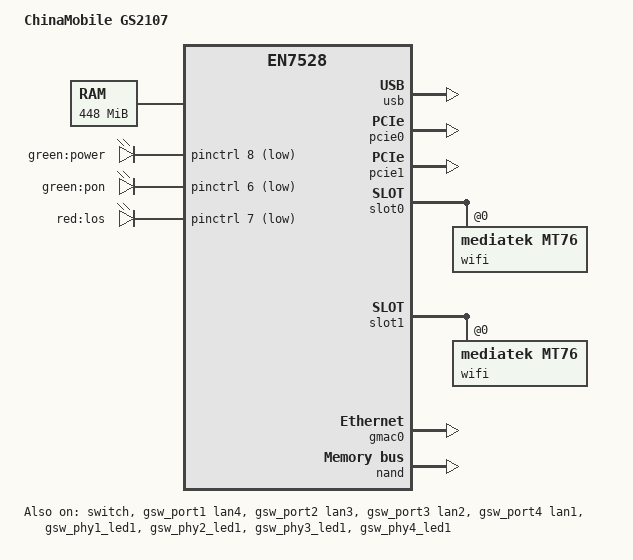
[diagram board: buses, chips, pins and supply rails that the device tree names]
// SPDX-License-Identifier: GPL-2.0-only OR BSD-2-Clause
/*
 * ChinaMobile GS2107（中移杭研智能家庭网关）— EcoNet EN7528
 *
 * 全部标注 [实测] 的事实来自 2026-11-06 亲验（devices/gs2107/ 下文档）：
 *  - SoC: EcoNet EN7528，MIPS1004Kc V2.15 双核 4 VPE，小端 [实测]
 *  - RAM: 运行时 MemTotal=410124kB；DDR 物理容量与厂商预留区待 VMLINUX-RE 确认
 *  - Flash: 256MB SPI NAND，11 分区（本 DTS 与 /proc/mtd 实测逐字节对齐）[实测]
 *  - WiFi: MT7603E(2.4G) + MT7663E(5G)，均 PCIe；
 *          domain0(pcie0)=MT7663E、domain1(pcie1)=MT7603E [实测 /sys/bus/pci]
 *  - 交换: EN7528 内置 GSW + 4 内部 GPHY [实测 eth.ko 的 macMT7530 API / EN7570]
 *  - MAC: bootloader 分区 +0x3fe48（与 JioFiber 同偏移）[实测]
 *  - Bootloader: ECNT tcboot，HDR2+LZMA 镜像，"free bootbase"（解压目标 0x80002000）[实测]
 *  - EEPROM: 2.4G 512B / 5G 1536B 在 rootfs 文件里，不在 NAND 固定偏移 [实测]
 *
 * 模板来源：OpenWrt master target/linux/econet（en7528.dtsi + jiofiber/dasan 板级文件），
 * JioFiber 与本机同 bootloader 变体（free bootbase / TRX_LOADADDR 0x80002000）。
 */

/dts-v1/;

#include "en7528.dtsi"

#include <dt-bindings/gpio/gpio.h>
#include <dt-bindings/input/input.h>
#include <dt-bindings/leds/common.h>

/ {
	model = "ChinaMobile GS2107";
	compatible = "chinamobile,gs2107", "econet,en7528";

	aliases {
		serial0 = &uart;
		led-boot = &led_power;
		led-failsafe = &led_power;
		led-running = &led_power;
		led-upgrade = &led_power;
	};

	memory@0 {
		device_type = "memory";
		/*
		 * 448MB 物理（VMLINUX-RE 实证：cal_qdma_init_buffer(448)；
		 * 运行时 MemTotal 410124kB ≈ 448MB - 约 47MB 内核 BSS/预留，
		 * 其中 BSS 0x80AE0000-0x81BB9B4C 达 17.9MB）。
		 * 构建配置 profile.cfg 的 TCSUPPORT_SDRAM_128M=y 已证伪（过期模板）。
		 * 与 JioFiber JCOW414 完全同值。
		 */
		reg = <0x00000000 0x1c000000>;
	};

	reserved-memory {
		#address-cells = <1>;
		#size-cells = <1>;
		ranges;

		/* 崩溃现场（pstore/ramoops）：panic、oops 与锁死检测触发的 panic 把内核日志写进这里，热复位（看门狗、sysrq、panic 重启）后由 /sys/fs/pstore 读出。放在 384 MB 处：U-Boot 只用 256 MB 以内（board_get_usable_ram_top 把重定位上限钳在 0x90000000），FIT 加载在 0x82000000；ecc-size 让被启动链覆盖的记录显出来而不是读成乱码。 */
		ramoops@18000000 {
			compatible = "ramoops";
			reg = <0x18000000 0x100000>;
			record-size = <0x20000>;
			console-size = <0x40000>;
			ecc-size = <16>;
		};

		/* U-Boot 启动计数（CONFIG_BOOTCOUNT_GENERIC，CONFIG_SYS_BOOTCOUNT_ADDR = 0xB8100000，即本处经 KSEG1 不缓存的地址）：两个小端 32 位字，偏移 0 是计数、偏移 4 是魔数 0xB001C041；U-Boot 每次启动读出加 1 再存，超过 bootlimit 走 altbootcmd，魔数不符（冷启动）按 0 算，热复位 DRAM 内容保持。紧跟 ramoops 之后，留一页。no-map：内核不把它当普通内存分配，由下面的 bootcount 节点（uboot-bootcount 驱动）按不缓存映射读写。 */
		bootcount_mem: bootcount@18100000 {
			reg = <0x18100000 0x1000>;
			no-map;
		};
	};

	/* 系统起来后由 gs2107-bootok 经这里把 U-Boot 的启动计数清零：uboot-bootcount 驱动给本设备一个 sysfs 属性 count（经 /sys/bus/platform/drivers/uboot-bootcount/ 下的设备链接访问），读出计数（魔数不符时为 0），写入 N 存计数 N 与魔数并读回核对。 */
	bootcount {
		compatible = "u-boot,bootcount-mem";
		memory-region = <&bootcount_mem>;
	};

	/* 命令行只来自 U-Boot：bootm 用 env 的 bootargs 改写 /chosen/bootargs，控制台由 stdout-path 给出。命令行不带 root=：根是 UBI 卷 rootfs，OpenWrt 491 在 attach 时为它建 ubiblock，493 在 ROOT_DEV 未设时把它设为根（devices/openwrt/gs2107 docs/33 §2.2）。 */
	chosen {
		stdout-path = "/serial@1fbf0000:115200";
	};

	/* UBI 设备 ubi_rootfs：&nand 里两段不相邻的分区 ubi_seg0、ubi_seg1 按地址顺序拼成一个 MTD，squashfs 根是卷 rootfs，overlay 是 UBIFS 卷 rootfs_data。attach 只靠 linux,ubi（ubi_notify_add，MTD 何时注册都能 attach）；自救 DTB 由本 DTB 去掉这一条派生，自救系统不自动 attach。分区名避开三个会被 OpenWrt 补丁按名字处理的名字：rootfs（hack 420 在 MTD 注册时把它设成根，抢在 UBI attach 之前）、ubi 与 data（pending 490 在 late_initcall 里自动 attach，自救 DTB 就没法只靠去掉 linux,ubi 保持不 attach）。 */
	ubi-concat {
		compatible = "mtd-concat";
		devices = <&ubi_seg0 &ubi_seg1>;

		partitions {
			compatible = "fixed-partitions";
			#address-cells = <1>;
			#size-cells = <1>;

			ubi_rootfs: partition@0 {	/* mtd8 209M（0x2000000 + 0xb100000），1672 PEB */
				label = "ubi_rootfs";
				reg = <0x0 0x0d100000>;
				compatible = "linux,ubi";
			};
		};
	};

	/*
	 * 面板灯（2026-11-11 固件分析结论）：
	 *  - 电源：GPIO8，低电平点亮。tcboot 启动时已把它拉低（实测 GPIO
	 *    寄存器：OE0 bit8=1、DATA0 bit8=0），所以 OpenWrt 不配也会常亮；
	 *    这里登记成 LED 设备，统一走 led-boot/led-running。
	 *  - PON/LOS：原厂 /userfs/led.conf 的 LED 64/65 -> GPIO6、66/67 ->
	 *    GPIO7（xpon.ko 的 change_alarm_led_status 实测传 0x40..0x43）。
	 *    注意：本机 GPIO6/7 的 mux 位本来就是 0，寄存器级实测可正常拉低/
	 *    拉高，但面板没有反应；这两颗灯很可能挂在 EN7571 PON PHY 的 LED
	 *    控制器上，只有 PON 驱动初始化后才可用。这里保留节点，等 PON 侧
	 *    有能力时直接接管，不让 GPIO 悬空。
	 *  - 网络：原厂 led.conf 的 INTERNET 行全为 0，xpon/tcledctrl 没有给出
	 *    任何 GPIO；没有可写的硬件映射，暂不建节点。
	 *  - 无线：驱动注册 /sys/class/leds/mt76-phy0|phy1，默认触发器 phy0tpt/phy1tpt。2.4G（MT7603E）由 mt76 写芯片 LED 控制器的 pin 0；5G（MT7663E）接在芯片的 LED1，由固件经 MCU 命令 EXT_CMD_ID_LED 驱动（mt76 补丁，见 slot0 的 led 节点）。
	 */
	leds {
		compatible = "gpio-leds";

		led_power: power {
			label = "green:power";
			gpios = <&pinctrl 8 GPIO_ACTIVE_LOW>;
			default-state = "on";
		};

		led_pon: pon {
			label = "green:pon";
			gpios = <&pinctrl 6 GPIO_ACTIVE_LOW>;
			default-state = "off";
		};

		led_los: los {
			label = "red:los";
			gpios = <&pinctrl 7 GPIO_ACTIVE_LOW>;
			default-state = "off";
		};
	};
};

&usb {
	status = "okay";
};

/*
 * 双 PCIe root complex [实测：/sys/bus/pci/devices]
 *   0000:00:00.0 (0x14c3:0x0810, domain0) → 01:00.0 = MT7663E (5G)
 *   0000:00:01.0 (0x14c3:0x0811, domain1) → 02:00.0 = MT7603E (2.4G)
 */
&pcie0 {
	status = "okay";
};

&pcie1 {
	status = "okay";
};

&slot0 {
	status = "okay";

	wifi@0,0 {
		compatible = "mediatek,mt76";
		reg = <0x0000 0 0 0 0>;
		nvmem-cells = <&macaddr_bl 2>;
		nvmem-cell-names = "mac-address";
		/*
		 * [11-08 硬编码] nvmem 在 mtd0（bootloader 分区 +0x3fe48），
		 * NAND 因 SFC strap 问题内核期不可见 → of_get_mac_address()
		 * 对缺失 nvmem provider 返回 -EPROBE_DEFER → 整棵 probe 挂起
		 * （ethernet/switch/两颗 wifi 全部 defer，devices_deferred 实证）。
		 * mac-base 布局语义 = 基址 + index：基址 b4:ba:12:5c:41:a0
		 * （mtd0+0x3fe48 实测 dump），index2 → …a2。
		 * mac-address 属性优先于 nvmem，NAND 恢复后两者取值一致。
		 */
		mac-address = [b4 ba 12 5c 41 a2];
		ieee80211-freq-limit = <5000000 6000000>;
		/*
		 * [11-11 5G 校准] 原厂运行期 eeprom（1536B，magic 0x7663）：
		 * firmware/runtime-config/tmp/etc/Wireless/RT2860AP_AC/RT30xxEEPROM.bin
		 * 源 sha256 d904523513ae23b527ee22267958cc169e6802a23b4eaa34c458a918b43468a7
		 * mt76 的 MT7663 eeprom 尺寸即 1536B（MT7663_EEPROM_SIZE）；
		 * mediatek,eeprom-data 经 mt76_get_of_eeprom_data() 读入，
		 * 允许 size <= MT7615_EEPROM_FULL_SIZE，无需额外 MTD 分区。
		 * eeprom 内 MAC 为 00:0c:43:26:60:00；上面的 mac-address 在
		 * mt76_eeprom_override() 中优先，本机 MAC 仍为 b4:ba:12:5c:41:a2。
		 * 2.4G 仍走 eFuse/默认值（当前 20 dBm），不在本条数据范围内。
		 */
		mediatek,eeprom-data = [
			63 76 00 01 00 0c 43 26 60 00 63 76 c3 14 00 80
			02 00 63 76 c3 14 00 00 00 00 00 00 00 00 00 00
			00 00 00 00 00 00 00 00 00 00 00 00 00 00 e3 00
			00 01 80 00 00 00 00 00 00 00 00 00 00 00 00 00
			00 00 00 00 00 00 00 00 00 00 98 00 00 00 01 00
			00 00 00 00 00 00 00 00 00 00 00 00 00 00 00 00
			18 04 54 60 aa 12 00 00 00 00 00 00 00 00 00 00
			c6 c6 c4 c4 c2 c1 00 c2 00 c2 c1 00 00 81 84 85
			c2 c2 c1 81 81 82 85 86 00 c3 c3 c2 c2 00 c1 00
			c1 c1 00 00 82 83 84 c1 c1 c1 00 00 82 83 84 00
			c1 c1 c1 00 00 82 83 84 00 00 00 00 00 00 00 00
			cb dc 1f 17 17 17 11 09 09 09 40 40 40 40 00 00
			00 00 00 00 00 00 00 00 00 00 00 00 00 00 00 00
			00 00 00 00 00 00 00 00 00 00 00 00 00 00 00 3c
			10 c3 c6 25 00 00 00 00 00 00 00 00 00 00 00 00
			10 43 c6 25 00 00 00 00 00 00 00 00 00 00 00 00
			00 00 00 00 00 00 00 00 00 00 00 00 00 00 00 00
			00 00 00 00 00 00 00 00 00 00 00 00 00 00 00 00
			00 00 00 00 00 00 00 00 bc 2b 40 5f 17 49 1c df
			00 00 00 00 00 00 00 00 00 00 00 00 00 00 00 00
			00 00 00 00 00 00 00 00 00 00 00 00 00 00 00 00
			00 00 00 00 08 00 e0 01 00 00 00 00 00 00 00 00
			00 00 00 00 00 00 00 00 00 00 00 00 00 00 00 00
			00 00 00 00 00 00 00 00 00 10 10 28 00 00 00 00
			00 00 00 00 00 00 00 00 00 00 00 00 00 00 00 00
			00 00 00 00 00 00 00 00 00 00 00 00 00 00 00 00
			00 00 00 00 00 00 00 00 00 00 00 00 00 00 00 00
			12 12 02 00 00 00 00 05 c4 c0 bc 00 85 00 00 00
			00 00 00 00 00 00 00 00 00 00 00 00 00 00 00 00
			00 00 00 00 00 00 00 00 00 00 00 00 00 00 00 00
			00 00 00 00 00 00 00 00 00 00 00 00 00 00 00 00
			cc d8 cc d8 cc d8 cc d8 cc d8 cc d8 cc d8 cc d8
			1f 12 12 12 13 06 06 06 40 40 40 40 00 00 00 00
			00 00 00 00 00 00 00 00 00 00 00 00 00 00 00 00
			00 00 00 00 00 00 00 00 00 00 00 00 00 00 00 00
			00 00 00 00 00 00 00 00 00 00 00 3a 00 00 00 00
			20 20 20 41 cb 24 41 cb 24 41 cb 24 41 cb 24 41
			cb 24 41 cb 24 41 cb 24 41 cb 24 00 00 00 00 00
			00 00 00 00 00 00 00 00 00 00 00 00 00 00 00 00
			00 00 00 00 00 00 00 00 00 00 00 00 00 00 00 00
			00 00 00 00 00 00 00 00 00 00 00 00 00 00 00 00
			00 00 00 00 00 00 00 00 00 00 00 00 00 00 00 00
			00 00 00 00 00 00 00 00 00 00 00 00 00 00 00 00
			20 20 20 41 cb 24 41 cb 24 41 cb 24 41 cb 24 41
			cb 24 41 cb 24 41 cb 24 41 cb 24 00 00 00 00 00
			00 00 00 00 00 00 00 00 00 00 00 00 00 00 00 00
			00 00 00 00 00 00 00 00 00 00 00 00 00 00 00 00
			00 00 00 00 00 00 00 00 00 00 00 00 00 00 00 00
			00 00 00 00 00 00 00 00 00 00 00 00 00 00 00 00
			00 00 00 00 00 00 00 00 00 00 00 00 00 00 00 00
			00 00 00 00 00 00 00 00 00 00 00 00 00 00 00 00
			00 00 00 00 00 00 00 00 00 00 00 00 00 00 00 00
			00 00 00 00 00 00 00 00 00 00 00 00 00 00 00 00
			00 00 00 00 00 00 00 00 00 00 00 00 00 00 00 00
			00 00 00 00 00 00 00 00 00 00 00 00 00 00 00 00
			00 00 00 00 00 00 00 00 00 00 00 00 00 00 00 00
			00 00 00 00 00 00 00 00 00 00 00 00 00 00 00 00
			00 00 00 00 00 00 00 00 00 00 00 00 00 00 00 00
			00 00 00 00 00 00 00 00 00 00 00 00 00 00 00 00
			00 00 00 00 00 00 00 00 00 00 00 00 00 00 00 00
			00 00 00 00 00 00 00 00 00 00 00 00 00 00 00 00
			00 00 00 00 00 00 00 00 00 00 00 00 00 00 00 00
			00 00 00 00 00 00 00 00 00 00 00 00 00 00 00 00
			00 00 00 00 00 00 00 00 00 00 00 00 00 00 00 00
			00 00 00 00 00 00 00 00 00 00 00 00 00 00 00 00
			00 00 00 00 00 00 00 00 00 00 00 00 00 00 00 00
			00 00 00 00 00 00 00 00 00 00 00 00 00 00 00 0f
			cb 98 41 04 07 53 20 00 06 00 00 00 00 00 00 00
			00 00 00 00 00 00 00 00 00 00 00 00 00 00 00 00
			00 00 00 00 00 00 00 00 00 00 00 00 00 00 00 00
			00 00 00 00 00 00 00 00 00 00 00 00 00 00 00 00
			00 00 00 00 00 00 00 00 00 00 00 00 00 00 00 00
			00 00 00 00 00 00 00 00 00 00 00 00 00 00 00 00
			00 00 00 00 00 00 00 00 00 00 00 00 00 00 00 00
			00 00 00 00 00 00 00 00 00 00 00 00 00 00 00 00
			00 00 00 00 00 00 00 00 00 00 00 00 00 00 00 00
			00 00 00 00 00 00 00 00 00 00 00 00 00 00 00 00
			00 00 00 00 00 00 00 00 00 00 00 00 00 00 00 00
			00 00 00 00 00 00 00 00 00 00 00 00 00 00 00 00
			00 00 00 00 00 00 00 00 00 00 00 00 00 00 00 00
			00 00 00 00 00 00 00 00 00 00 00 00 00 00 00 00
			00 00 00 00 00 00 00 00 00 00 00 00 00 00 00 00
			00 00 00 00 00 00 00 00 00 00 00 00 00 00 00 00
			00 00 00 00 00 00 00 00 00 00 00 00 00 00 00 00
			00 00 00 00 00 00 00 00 00 00 00 00 00 00 00 00
			00 e0 07 00 00 00 00 00 00 00 00 00 00 00 00 00
			00 00 00 00 00 00 00 00 00 00 00 00 00 00 00 00
			00 00 00 00 00 00 00 00 00 00 00 00 00 00 00 00
			00 00 00 00 00 00 00 00 00 00 00 00 00 00 00 00
			00 00 00 00 00 00 00 00 00 00 00 00 00 00 00 00
			00 00 00 00 00 00 00 00 00 00 00 00 00 00 00 00
			00 00 00 00 00 00 00 00 00 00 00 00 00 00 00 00
			00 00 00 00 00 00 00 00 00 00 00 00 00 00 00 00
			00 00 00 00 00 00 00 00 00 00 00 00 00 00 00 00
			00 00 00 00 00 00 00 00 00 00 00 00 00 00 00 00
			00 00 00 00 00 00 00 00 00 00 00 00 00 00 00 00
		];

		/* 5G 灯：MediaTek 的 mt_wifi 对 MT7663 固定用 LED1（原厂内核逆向，docs/28），mt76 的 MT7663 补丁缺省也是 1，这里写明板级事实；原厂不置反极性，不加 led-active-low */
		led {
			led-sources = <1>;
		};
	};
};

&slot1 {
	status = "okay";

	wifi@0,0 {
		compatible = "mediatek,mt76";
		reg = <0x0000 0 0 0 0>;
		nvmem-cells = <&macaddr_bl 3>;
		nvmem-cell-names = "mac-address";
		/* [11-08 硬编码] 同 slot0：基址+index3 → …a3 */
		mac-address = [b4 ba 12 5c 41 a3];
		ieee80211-freq-limit = <2400000 2500000>;
		/*
		 * [11-11 2.4G 校准] 原厂运行期 eeprom（512B，magic 0x7592）载荷；
		 * mt76 MT7603 要求 0x000 = 0x7603/0x7628/0x7600，故把首 2B
		 * 规范为 0x7603，并按 MT7603_EEPROM_SIZE=1024 补零到 1024B。
		 * 源：firmware/runtime-config/tmp/etc/RT30xxEEPROM.bin
		 * 源 sha256 e8fd5884cfabfb5d2d4cfaa927307d6cb6317da7372c2493045865dd5a0e38b8
		 * 转换后 1024B sha256 49010abcada5a92e42f1a0aeb782e6ff6060c71d066b1ee3ae282319627b50a9
		 * 所有 mt7603 消费字段 <0x13e，上半 512B 不被读取；DT
		 * mac-address 仍覆盖 eeprom 内 MAC（00:0c:43:26:60:40）。
		 */
		mediatek,eeprom-data = [
			03 76 0f 00 00 0c 43 26 60 40 03 76 c3 14 ff ff
			ff ff 03 76 c3 14 00 00 00 00 00 00 00 00 00 00
			00 00 b0 07 80 00 60 7f fd 9b ff ff ff ff ff ff
			ff ff ff ff 22 34 00 20 ff ff 00 01 00 00 00 00
			00 00 22 00 00 00 00 00 00 00 00 00 00 00 e0 01
			81 00 00 94 40 b8 40 c8 20 c1 c1 c1 40 c8 20 c2
			c1 c1 00 00 00 00 00 00 00 00 00 00 00 00 00 00
			ff ff ff ff ff ff ff ff ff ff ff ff ff ff ff ff
			ff ff ff ff ff ff ff ff ff ff ff ff ff ff ff ff
			00 00 00 00 00 00 00 00 00 00 00 00 00 00 00 00
			c6 c6 c4 c4 c4 c0 c0 c4 c4 c4 c4 c0 c0 c0 00 00
			ff ff ff ff ff ff ff ff ff ff ff ff ff ff ff ff
			ff ff ff ff ff ff ff ff ff ff ff ff ff ff ff ff
			ff ff ff ff ff ff ff ff ff ff ff ff ff ff ff ff
			ff ff ff ff ff ff ff ff ff ff ff ff ff ff ff ff
			05 00 00 00 ac 80 82 88 00 00 00 00 00 00 00 00
			ff ff ff ff ff ff ff ff ff ff ff ff ff ff ff ff
			ff ff ff ff ff ff ff ff ff ff ff ff ff ff ff ff
			00 00 00 00 00 00 00 00 00 00 00 00 00 00 ff 20
			ff ff ff ff ff ff ff ff ff ff ff ff ff ff ff ff
			ff ff ff ff ff ff ff ff ff ff ff ff ff ff ff ff
			ff ff ff ff ff ff ff ff ff ff ff ff ff ff ff ff
			ff ff ff ff ff ff ff ff ff ff ff ff ff ff ff ff
			ff ff ff ff ff ff ff ff ff ff ff ff ff ff ff ff
			ff ff ff ff ff ff ff ff ff ff ff ff ff ff ff ff
			ff ff ff ff ff ff ff ff ff ff ff ff ff ff ff ff
			ff ff ff ff ff ff ff ff ff ff ff ff ff ff ff ff
			ff ff ff ff ff ff ff ff ff ff ff ff ff ff ff ff
			ff ff ff ff ff ff ff ff ff ff ff ff ff ff ff ff
			ff ff ff ff ff ff ff ff ff ff ff ff ff ff ff ff
			ff ff ff ff ff ff ff ff ff ff ff ff ff ff ff ff
			ff ff ff ff ff ff ff ff ff ff ff ff ff ff ff ff
			00 00 00 00 00 00 00 00 00 00 00 00 00 00 00 00
			00 00 00 00 00 00 00 00 00 00 00 00 00 00 00 00
			00 00 00 00 00 00 00 00 00 00 00 00 00 00 00 00
			00 00 00 00 00 00 00 00 00 00 00 00 00 00 00 00
			00 00 00 00 00 00 00 00 00 00 00 00 00 00 00 00
			00 00 00 00 00 00 00 00 00 00 00 00 00 00 00 00
			00 00 00 00 00 00 00 00 00 00 00 00 00 00 00 00
			00 00 00 00 00 00 00 00 00 00 00 00 00 00 00 00
			00 00 00 00 00 00 00 00 00 00 00 00 00 00 00 00
			00 00 00 00 00 00 00 00 00 00 00 00 00 00 00 00
			00 00 00 00 00 00 00 00 00 00 00 00 00 00 00 00
			00 00 00 00 00 00 00 00 00 00 00 00 00 00 00 00
			00 00 00 00 00 00 00 00 00 00 00 00 00 00 00 00
			00 00 00 00 00 00 00 00 00 00 00 00 00 00 00 00
			00 00 00 00 00 00 00 00 00 00 00 00 00 00 00 00
			00 00 00 00 00 00 00 00 00 00 00 00 00 00 00 00
			00 00 00 00 00 00 00 00 00 00 00 00 00 00 00 00
			00 00 00 00 00 00 00 00 00 00 00 00 00 00 00 00
			00 00 00 00 00 00 00 00 00 00 00 00 00 00 00 00
			00 00 00 00 00 00 00 00 00 00 00 00 00 00 00 00
			00 00 00 00 00 00 00 00 00 00 00 00 00 00 00 00
			00 00 00 00 00 00 00 00 00 00 00 00 00 00 00 00
			00 00 00 00 00 00 00 00 00 00 00 00 00 00 00 00
			00 00 00 00 00 00 00 00 00 00 00 00 00 00 00 00
			00 00 00 00 00 00 00 00 00 00 00 00 00 00 00 00
			00 00 00 00 00 00 00 00 00 00 00 00 00 00 00 00
			00 00 00 00 00 00 00 00 00 00 00 00 00 00 00 00
			00 00 00 00 00 00 00 00 00 00 00 00 00 00 00 00
			00 00 00 00 00 00 00 00 00 00 00 00 00 00 00 00
			00 00 00 00 00 00 00 00 00 00 00 00 00 00 00 00
			00 00 00 00 00 00 00 00 00 00 00 00 00 00 00 00
			00 00 00 00 00 00 00 00 00 00 00 00 00 00 00 00
		];
	};
};

&gmac0 {
	status = "okay";
	nvmem-cells = <&macaddr_bl 1>;
	nvmem-cell-names = "mac-address";
	/*
	 * [11-08 硬编码] 原厂 eth0 实测 MAC = 基址本身 b4:ba:12:5c:41:a0
	 * （stock bootlog: "eth0: FE MAC Ethernet address: B4:BA:12:5C:41:A0"），
	 * 故此处不用 macaddr_bl 1（基址+1=…a1）。理由同 slot0 注释：
	 * 属性优先于 nvmem，绕开 NAND 不可见导致的 probe defer。
	 */
	mac-address = [b4 ba 12 5c 41 a0];
};

&switch {
	status = "okay";
};

/* 四口同构（GSW 内置 PHY）；ROMFILE 的 ONU 画像报 GEPortNum=1 + FEPortNum=3，OMCI 报 4 桥端口。端口标签与面板网口编号一致（用户 2026-11-22 定）：交换机端口 1–4 在面板上依次是网口 4–1（2026-11-15 插线实测网口 1 与 4，网口 2、3 按反序推断，见 docs/28 §2.2），所以 gsw_port1 标 lan4……gsw_port4 标 lan1。lan4（面板网口 4）由 board.d/02_network 配成 WAN（DHCP 客户端），lan1–lan3 进 LAN 桥。 */
&gsw_port1 {
	label = "lan4";
	status = "okay";
};

&gsw_port2 {
	label = "lan3";
	status = "okay";
};

&gsw_port3 {
	label = "lan2";
	status = "okay";
};

&gsw_port4 {
	label = "lan1";
	status = "okay";
};

/*
 * LAN1-4 面板灯：EN7528 的 GSW PHY LED1 通过 GPIO31/33/35/37 的
 * LAN0..3_LED1 复用功能引出。tcboot 启动时已经把 0x1fa2015c 的
 * bit5/7/9/11 置位（实测该寄存器 = 0x2aa0），并把 0x1fa201b0/1b4
 * 的映射写成 0x43210；这里用 pinctrl 状态把同一组 mux 再声明一次，
 * 让 mtk-ge-soc 的 "gbe-led" 路径在 probe 时显式选中它。
 */
&pinctrl {
	gswp1_led1_pins: gswp1-led1-pins {
		mux {
			function = "phy1_led1";
			groups = "gpio31";
		};
	};

	gswp2_led1_pins: gswp2-led1-pins {
		mux {
			function = "phy2_led1";
			groups = "gpio33";
		};
	};

	gswp3_led1_pins: gswp3-led1-pins {
		mux {
			function = "phy3_led1";
			groups = "gpio35";
		};
	};

	gswp4_led1_pins: gswp4-led1-pins {
		mux {
			function = "phy4_led1";
			groups = "gpio37";
		};
	};
};

&gsw_phy1 {
	pinctrl-names = "gbe-led";
	pinctrl-0 = <&gswp1_led1_pins>;
};

&gsw_phy2 {
	pinctrl-names = "gbe-led";
	pinctrl-0 = <&gswp2_led1_pins>;
};

&gsw_phy3 {
	pinctrl-names = "gbe-led";
	pinctrl-0 = <&gswp3_led1_pins>;
};

&gsw_phy4 {
	pinctrl-names = "gbe-led";
	pinctrl-0 = <&gswp4_led1_pins>;
};

&gsw_phy1_led1 {
	color = <LED_COLOR_ID_GREEN>;
	function = LED_FUNCTION_LAN;
	function-enumerator = <4>;
	linux,default-trigger = "netdev";
	active-low;
	status = "okay";
};

&gsw_phy2_led1 {
	color = <LED_COLOR_ID_GREEN>;
	function = LED_FUNCTION_LAN;
	function-enumerator = <3>;
	linux,default-trigger = "netdev";
	active-low;
	status = "okay";
};

&gsw_phy3_led1 {
	color = <LED_COLOR_ID_GREEN>;
	function = LED_FUNCTION_LAN;
	function-enumerator = <2>;
	linux,default-trigger = "netdev";
	active-low;
	status = "okay";
};

&gsw_phy4_led1 {
	color = <LED_COLOR_ID_GREEN>;
	function = LED_FUNCTION_LAN;
	function-enumerator = <1>;
	linux,default-trigger = "netdev";
	active-low;
	status = "okay";
};

&nand {
	status = "okay";
	econet,bmt;
	econet,bbt-table-size = <250>;

	partitions {
		compatible = "fixed-partitions";
		#address-cells = <1>;
		#size-cells = <1>;

		/*
		 * 分区按地址排（节点顺序即 mtd 编号），128 KiB 块对齐、互不重叠；布局的唯一来源是设备目录的 tools/u-boot/layout.py（devices/openwrt/gs2107 docs/33 §1.3），文件系统取舍见同目录 docs/15。
		 * 启动链：tcboot（bootloader，唯一启动入口）固定从 0x80000 读 HDR2，所以 uboot 槽从 0x80000 起，里面是 uboot.hdr2（stub 把内嵌的 U-Boot 搬到 0x81000000 再跳过去）；U-Boot 读 kernel（内核 FIT）后 bootm，不碰 UBI 区。板载闪存上不放自救镜像：自救 FIT 留在开发机上，作网络救援件经 TFTP 载入内存。
		 * Linux 不写 bootloader、romfile、reservearea：romfile 是厂商配置的唯一副本，tcboot 不读它（docs/23 §4）；reservearea 的 +0x200000（芯片偏移 0xDFC0000）是 tcboot 的 A/B 旗标。
		 * ubi_seg0（原 rootfs 区）与 ubi_seg1（原 recovery 与 rootfs_data 两区，地址相连）是根节点下 ubi-concat 的成员段，拼成 UBI 设备 ubi_rootfs；工具只经 ubi_rootfs 上的 UBI 写这两段，成员段上的原始写入会绕过 UBI。两段都不开 econet,enable-remap：坏块由 UBI 自己处理（en75_bmt.c 头部注释同样要求 UBI 分区不开 remap）。
		 * 空间账：0x80000 起共 0xDD40000（221.25 MiB）= uboot 4M + kernel 8M + ubi_seg0 32M + uboot_env 256K + ubi_seg1 177M，到 reservearea 前一刻；ubi_rootfs = 32M + 177M = 209M（1672 PEB）。0xE000000 起是 en75_bmt 用户区余下的块与 BMT 保留池，不分区。
		 */
		partition@0 {			/* mtd0 256K */
			label = "bootloader";
			reg = <0x00000000 0x00040000>;
			read-only;

			nvmem-layout {
				compatible = "fixed-layout";
				#address-cells = <1>;
				#size-cells = <1>;

				/* [实测] MAC b4:ba:12:5c:41:a0 就在 0x3fe48，与 JioFiber 同偏移 */
				macaddr_bl: macaddr@3fe48 {
					compatible = "mac-base";
					reg = <0x3fe48 0x6>;
					#nvmem-cell-cells = <1>;
				};
			};
		};

		partition@40000 {			/* mtd1 256K */
			label = "romfile";
			reg = <0x00040000 0x00040000>;
			read-only;
		};

		/*
		 * uboot：不死 u-boot 槽。bootbase 固定从 0x80000 读 HDR2 并解压到
		 * 0x80002000，故本槽必须从 0x80000 起。4MB。
		 * 现居者 = uboot.hdr2（stub + 内嵌 U-Boot，见上方分区表注释）。
		 */
		partition@80000 {			/* mtd2 4M */
			label = "uboot";
			reg = <0x00080000 0x00400000>;
		};

		/*
		 * kernel：内核 FIT（vmlinuz.bin + DTB），由 U-Boot 读出（gs_nand_boot）并 bootm，不由 bootbase 直接读。
		 * 不开 econet,enable-remap：开了以后内核以 ECC 读这里、纠错到阈值时会自行把整块搬进保留区并重写 BMT 表，而 BMT 表也是 tcboot 取 mtd2 要用的启动相关存储，改写只经带确认门的工具做。块变弱由每周巡读的纠错增量报警，重写内核即刷新，真磨坏了再用 tools/openwrt/gs2107-nand-repair.sh 重映射：它经 debugfs 的 mtk-bmt/en75_remap 请求，en75_bmt 只对带 econet,manual-remap 的分区受理这种显式请求。本表只有 kernel 带它：由 U-Boot 整块读出、运行中没人读写的静态镜像分区；bootloader、romfile、uboot、uboot_env、reservearea 不带，UBI 的两个成员段 ubi_seg0、ubi_seg1 也不带（坏块由 UBI 处理）。
		 */
		partition@480000 {			/* mtd3 8M */
			label = "kernel";
			reg = <0x0480000 0x00800000>;
			econet,manual-remap;
		};

		ubi_seg0: partition@c80000 {		/* mtd4 32M：ubi-concat 第 1 段（原 rootfs 区） */
			label = "ubi_seg0";
			reg = <0x00c80000 0x02000000>;
		};

		/* uboot_env：两份 128KB 的冗余 U-Boot env。 */
		partition@2c80000 {		/* mtd5 256K */
			label = "uboot_env";
			reg = <0x02c80000 0x00040000>;
		};

		ubi_seg1: partition@2cc0000 {		/* mtd6 177M：ubi-concat 第 2 段（原 recovery 与 rootfs_data 两区） */
			label = "ubi_seg1";
			reg = <0x02cc0000 0x0b100000>;
		};

		/*
		 * reservearea：A/B flag 在 +0x200000（芯片偏移 0xDFC0000，单字节 ASCII
		 * '0'=主 / '1'=slave）。tcboot 只在主备切换时写它：主槽失败改起
		 * slave 时写 '1'，旗标为 '1' 而 slave 失败改起主槽时写 '0'（docs/23 §3.1）；
		 * 正常从主槽启动不写。OpenWrt 永不写入。
		 */
		partition@ddc0000 {		/* mtd7 2.25M */
			label = "reservearea";
			reg = <0x0ddc0000 0x00240000>;
			read-only;
		};
	};
};
